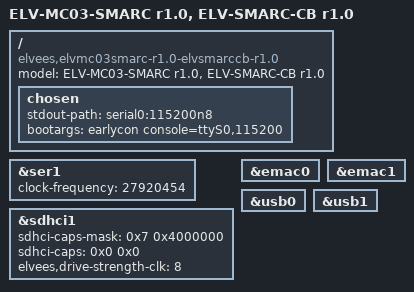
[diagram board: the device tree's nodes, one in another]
// SPDX-License-Identifier: GPL-2.0+
/*
 * Copyright 2022 RnD Center "ELVEES", JSC
 */

/dts-v1/;

#include <dt-bindings/gpio/gpio.h>

#include "mcom03-elvmc03smarc-r1.0.dtsi"

/ {	model = "ELV-MC03-SMARC r1.0, ELV-SMARC-CB r1.0";
	compatible = "elvees,elvmc03smarc-r1.0-elvsmarccb-r1.0",
		     "elvees,elvmc03smarc-elvsmarccb",
		     "elvees,elvsmarccb-r1.0",
		     "elvees,elvsmarccb",
		     "elvees,elvmc03smarc-r1.0",
		     "elvees,elvmc03smarc",
		     "elvees,mcom03";

	chosen {
		stdout-path = "serial0:115200n8";
		bootargs = "earlycon console=ttyS0,115200";
	};
};

/* Connected to USB Type-C Debug UART */
&ser1 {
	status = "okay";
	clock-frequency = <27920454>;
};

&sdhci1 {
	status = "okay";

	/* Disable 1.8V support
	 * Disable SDR50, SDR104 and DDR50 support
	 */
	sdhci-caps-mask = <0x7 0x4000000>;
	sdhci-caps = <0x0 0x0>;

	/* The default clock pad drive strength of 6 mA is insufficient
	 * for ELV-SMARC-CB resulting in unstable SDMMC performance
	 * (possibly due to a PCB bug).
	 */
	elvees,drive-strength-clk = <8>;
};

&emac0 {
	status = "okay";
};

&emac1 {
	status = "okay";
};

/* Connected to USB 3.0 hub */
&usb0 {
	status = "okay";
};

/* Connected to USB 2.0 hub */
&usb1 {
	status = "okay";
};
